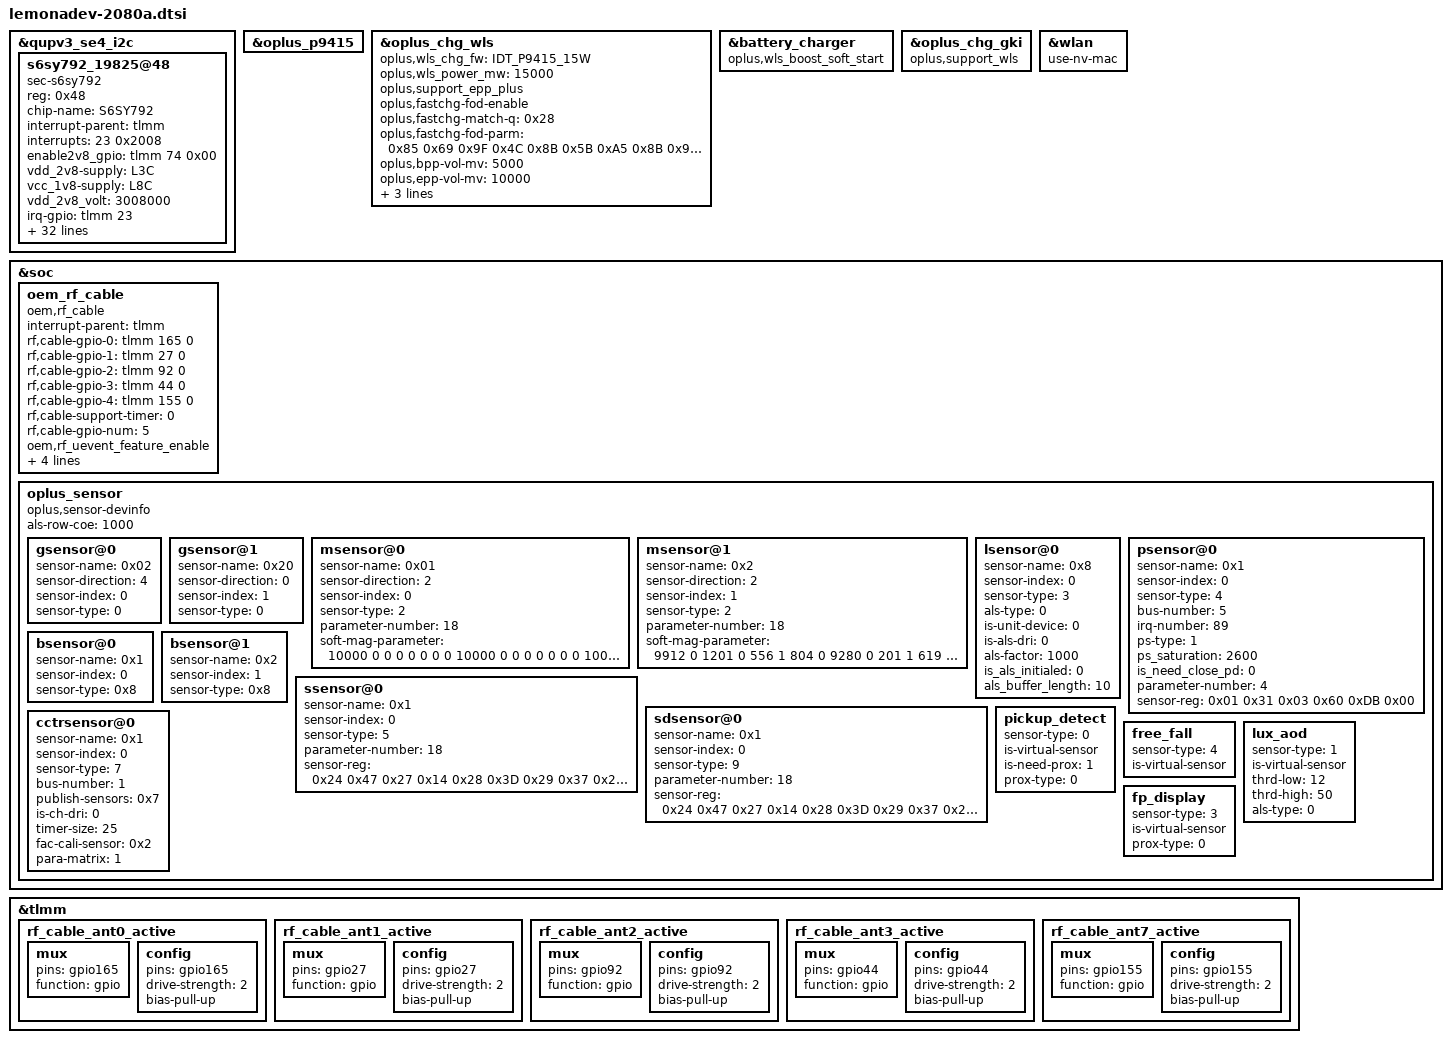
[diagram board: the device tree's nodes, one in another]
/*this is for different project dtsi*/
&qupv3_se4_i2c {
	status = "okay";
	s6sy792_19825@48 {
		compatible = "sec-s6sy792";
		reg = <0x48>;
		chip-name = "S6SY792";

		/* Interrupt && Irq-gpio */
		interrupt-parent = <&tlmm>;
		interrupts = <23 0x2008>;

		/* Power Config */
		enable2v8_gpio = <&tlmm 74 0x00>;
		//enable1v8_gpio = <&tlmm 6 0x1>;
		vdd_2v8-supply = <&L3C>;
		//vcc_1v8-supply = <&S1C>;
		vcc_1v8-supply = <&L8C>;
		vdd_2v8_volt = <3008000>;

		/* Other HW Resource */
		irq-gpio = <&tlmm 23 0x2008>;
		reset-gpio = <&tlmm 22 0x1>;
		pinctrl-names = "default";
		pinctrl-0 = <&ts_int_active &ts_reset_active>;

		touchpanel,max-num-support = <10>;
		touchpanel,tx-rx-num = <16 36>;
		earsense,tx-rx-num = <16 36>;
		touchpanel,panel-coords = <1079 2399>;
		touchpanel,display-coords = <1079 2399>;
		touchpanel,touchmajor-limit = <32 54>;
		project_id = <19825 20854>;

		vid_len = <2>;
		panel_type = <8>;
		platform_support_project = <19825 20854>;
		platform_support_project_dir = <19825 19825>;
		platform_support_project_commandline = "qcom,mdss_dsi_samsung_amb655x_dsc_cmd";

		/* SW Support Feature Control */
		//ear_sense_support;
		black_gesture_support;
		fw_edge_limit_support;
		charger_pump_support;
		//spurious_fingerprint_support;
		fw_update_app_support;
		smart_gesture_support;
		game_switch_support;
		//kernel_grip_support;
		fingerprint_underscreen_support;
		headset_pump_support;
		pressure_report_support;
		irq_need_dev_resume_ok;
		report_rate_white_list_support;
		temperature_detect_support;
		io-channels = <&pmk8350_vadc PM8350_ADC7_AMUX_THM3_100K_PU>;
		io-channel-names = "pm8350_hot_pocket_therm";
		oplus,skin_temp_chan = "pm8350_hot_pocket_therm";
		/*
		*Virtual Key Config:
		*1:touchpanel,button-type: <virtualkey_type  supportted_button-map>
		*virtualkey_type:
		*Type 1: using board_properties
		*Type 2: using same IC (button zone&& touch zone are seprate)
		*Type 3: using diffrent IC (button zone&& touch zone are seprate)
		*Type 4: No need of virtual key process
		*supportted_button-map:select|menu|home|back
		*
		*2:touchpanel,button-map
		*type (X1,Y1)(X2,Y2)(X3,Y3)(Width_X,Hight_Y)--Only when button-type is 0
		*/
		touchpanel,button-type = <4>;
		touchpanel.button-TRx = <0 0>;
	};
};

&oplus_p9415 {
	status = "ok";
};

&oplus_chg_wls {
	status = "ok";
	oplus,wls_chg_fw = "IDT_P9415_15W";
	oplus,wls_power_mw = <15000>;
	oplus,support_epp_plus;

	/* fod parameter*/
	oplus,fastchg-fod-enable;
	oplus,fastchg-match-q = /bits/ 8 <0x28>;
	oplus,fastchg-fod-parm = /bits/ 8 <0x85 0x69 0x9F 0x4C 0x8B 0x5B
						0xA5 0x8B 0x9C 0x0E 0x96 0x5A>;

	oplus,bpp-vol-mv = <5000>;
	oplus,epp-vol-mv = <10000>;
	oplus,epp_plus-vol-mv = <10000>;
	oplus,warp-vol-mv = <10000>;
	oplus,swarp-vol-mv = <12000>;
};

&battery_charger {
	oplus,wls_boost_soft_start;
};

&oplus_chg_gki {
	oplus,support_wls;
};
//#ifdef OPLUS_BUG_STABILITY
&wlan {
	use-nv-mac;
};
//#endif /* OPLUS_BUG_STABILITY */
//#ifdef OPLUS_FEATURE_TP_BASIC
&soc {
	//#ifdef OPLUS_FEATURE_RF_CABLE_DETECT
	oem_rf_cable:oem_rf_cable{
		compatible = "oem,rf_cable";
		interrupt-parent = <&tlmm>;
		rf,cable-gpio-0 = <&tlmm 165 0>;
		rf,cable-gpio-1 = <&tlmm 27 0>;
		rf,cable-gpio-2 = <&tlmm 92 0>;
		rf,cable-gpio-3 = <&tlmm 44 0>;
		rf,cable-gpio-4 = <&tlmm 155 0>;
		rf,cable-support-timer = <0>;
		rf,cable-gpio-num = <5>;
		oem,rf_uevent_feature_enable;
		pinctrl-names = "oem_rf_cable_active";
		pinctrl-0= <&rf_cable_ant0_active &rf_cable_ant1_active &rf_cable_ant2_active&rf_cable_ant3_active &rf_cable_ant7_active>;
	};
	//#endif /* OPLUS_FEATURE_RF_CABLE_DETECT */
	//#ifdef OPLUS_FEATURE_SENSOR_SMEM
	/*enum sensor_id { OPLUS_ACCEL,OPLUS_GYRO,OPLUS_MAG,OPLUS_LIGHT,OPLUS_PROXIMITY,OPLUS_SAR,OPLUS_CT,OPLUS_BAROMETER,SENSORS_NUM};*/
	oplus_sensor {
		compatible = "oplus,sensor-devinfo";
		als-row-coe = <1000>;
		/*enum {LSM6DSM = 0x01, BMI160 = 0x02, LSM6DS3 = 0x04, BMI260 = 0x08, LSM6DSO = 0x10,ICM4X6XX = 0x20,};*/
		gsensor@0 {
			sensor-name = <0x02>;//BMI160
			sensor-direction = <4>;
			sensor-index = <0>;//source num
			sensor-type = <0>;//OPLUS_ACCEL
		};
		gsensor@1 {
			sensor-name = <0x20>;//ICM4X6XX
			sensor-direction = <0>;
			sensor-index = <1>;//source num
			sensor-type = <0>;//OPLUS_ACCEL
		};
		/* enum {AKM0991X = 0x01, MMC5x3x = 0x02};*/
		msensor@0 {
			sensor-name = <0x01>;//AKM0991X
			sensor-direction = <2>;
			sensor-index = <0>;
			sensor-type = <2>;//OPLUS_MAG
			parameter-number= <18>;
			soft-mag-parameter = <10000 0 0 0 0 0 0 0 10000 0 0 0 0 0 0 0 10000 0>;//e00 sign e01 sign...
		};
		msensor@1 {
			sensor-name = <0x2>;//MMC5x3x
			sensor-direction = <2>;
			sensor-index = <1>;
			sensor-type = <2>;//OPLUS_MAG
			parameter-number= <18>;
			soft-mag-parameter = <9912 0 1201 0 556 1 804 0 9280 0 201 1 619 0 247 1 10492 0>;//e00 sign e01 sign...
		};
		/*enum {STK3A5X=0x01,TCS3701=0x02,TCS3408=0x04};*/
		lsensor@0 {
			sensor-name = <0x8>;//TCS3701 use see driver
			sensor-index = <0>;
			sensor-type = <3>;//OPLUS_LIGHT
			als-type = <0>;
			is-unit-device = <0>;
			is-als-dri = <0>;
			als-factor = <1000>;
			is_als_initialed = <0>;
			als_buffer_length = <10>;
		};
		psensor@0 {
			sensor-name = <0x1>;//STK33502
			sensor-index = <0>;
			sensor-type = <4>;//OPLUS_PROXIMITY
			bus-number = <5>;
			irq-number = <89>;
			ps-type = <1>;
			ps_saturation = <2600>;
			/*1-need close 2-close has contidition 0-not close*/
			is_need_close_pd = <0>;
			/*sensor-reg start*/
			parameter-number = <4>;
			sensor-reg = <0x01 0x31
				0x03 0x60
				0xDB 0x00>; //override special reg
			/*sensor-reg end*/
		};
 		/*enum {LPS22HH = 0x01, BMP380 = 0x02}*/
 		bsensor@0 {
 			sensor-name = <0x1>;//LPS22HH
 			sensor-index = <0>;
 			sensor-type = <0x8>;//BAROMETER
 		};
 		bsensor@1 {
 			sensor-name = <0x2>;//BMP380
 			sensor-index = <1>;
 			sensor-type = <0x8>;//BAROMETER
 		};
		/* enum {SX9324 = 0x01} */
		ssensor@0 {
			sensor-name = <0x1>;//SX9324
			sensor-index = <0>;
			sensor-type = <5>;//OPLUS_SAR
			parameter-number = <18>;
			sensor-reg = <0x24 0x47 0x27 0x14 0x28 0x3D 0x29 0x37 0x2a 0x1F 0x40 0x0B 0x41 0x0B 0x45 0x23 0x11 0x27>;
		};
		sdsensor@0 {
			sensor-name = <0x1>;//SX9324 DOWN
			sensor-index = <0>;
			sensor-type = <9>;//OPLUS_SAR
			parameter-number = <18>;
			sensor-reg = <0x24 0x47 0x27 0x14 0x28 0x3D 0x29 0x37 0x2a 0x1F 0x40 0x0B 0x41 0x0B 0x45 0x23 0x11 0x27>;
		};
		/* enum {tcs3408 = 0x01  tcs3701 = 0x02} */
		//cctsensor@0 {
	//        sensor-name = <0x2>; //tcs3701
	//        sensor-index = <0>;
	//        sensor-type = <6>; //OPLUS_CCT
	//        bus-number = <5>;
	//        //feature
	//        publish-sensors = <0x3>; //bit[0] - als, bit[1] - rgb, bit[2] - flicker
	//        is-ch-dri = <0>;
	//        timer-size = <25>; //ms
	//        fac-cali-sensor = <0x2>; //0x1 - als, 0x2 - rgb, 0x4, flicker
	//};
		cctrsensor@0 {
			sensor-name = <0x1>; //tcs3408
			sensor-index = <0>;
			sensor-type = <7>; //OPLUS_CCT_REAR
			bus-number = <1>;
			//feature
			publish-sensors = <0x7>; //bit[0] - als, bit[1] - rgb, bit[2] - flicker
			is-ch-dri = <0>;
			timer-size = <25>; //ms
			fac-cali-sensor = <0x2>; //0x1 - als, 0x2 - rgb, 0x4, flicker
                        para-matrix = <1>; //id_1 for 19825
		};
		/*virtual sensor
		enum sensor_algo_id {
			OPLUS_PICKUP_DETECT,
			OPLUS_LUX_AOD,
			OPLUS_TP_GESTURE,
			OPLUS_FP_DISPLAY,
			OPLUS_FREE_FALL,
			OPLUS_CAMERA_PROTECT,
			SENSOR_ALGO_NUM
		}*/
		pickup_detect {
			sensor-type = <0>;//OPLUS_PICKUP_DETECT
			is-virtual-sensor;
			is-need-prox = <1>;
			prox-type = <0>; // 0 - proximity; 1 - proximity_fake
		};
		free_fall {
			sensor-type = <4>;//OPLUS_FREE_FALL
			is-virtual-sensor;
		};
		lux_aod {
			sensor-type = <1>; //OPLUS_LUX_AOD
			is-virtual-sensor;
			thrd-low = <12>;
			thrd-high = <50>;
			als-type = <0>;
		};
		fp_display {
			sensor-type = <3>;//OPLUS_FP_DISPLAY
			is-virtual-sensor;
			prox-type = <0>; // 0 - proximity; 1 - proximity_fake
		};
	};
	//#endif /*OPLUS_FEATURE_SENSOR_SMEM*/
};
//#ifdef OPLUS_FEATURE_RF_CABLE_DETECT
&tlmm {
    rf_cable_ant0_active: rf_cable_ant0_active {
        mux {
            pins = "gpio165";
            function = "gpio";
        };
        config {
            pins = "gpio165";
            drive-strength = <2>;
            bias-pull-up;
        };
    };
	rf_cable_ant1_active: rf_cable_ant1_active {
        mux {
            pins = "gpio27";
            function = "gpio";
        };
        config {
            pins = "gpio27";
            drive-strength = <2>;
            bias-pull-up;
        };
    };
	rf_cable_ant2_active: rf_cable_ant2_active {
        mux {
            pins = "gpio92";
            function = "gpio";
        };
        config {
            pins = "gpio92";
            drive-strength = <2>;
            bias-pull-up;
        };
    };
	rf_cable_ant3_active: rf_cable_ant3_active {
        mux {
            pins = "gpio44";
            function = "gpio";
        };
        config {
            pins = "gpio44";
            drive-strength = <2>;
            bias-pull-up;
        };
    };
	rf_cable_ant7_active: rf_cable_ant7_active {
        mux {
            pins = "gpio155";
            function = "gpio";
        };
        config {
            pins = "gpio155";
            drive-strength = <2>;
            bias-pull-up;
        };
    };
};
//#endif /* OPLUS_FEATURE_RF_CABLE_DETECT */
//#endif /* OPLUS_FEATURE_TP_BASIC */
